VERSION ""

NS_ :

BS_:

BU_:

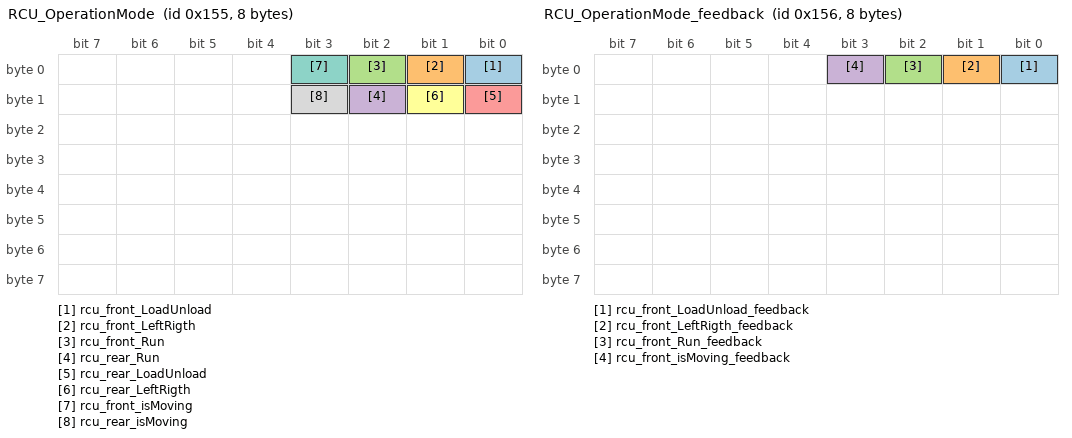
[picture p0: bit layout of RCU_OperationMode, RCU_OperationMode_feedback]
BO_ 341 RCU_OperationMode: 8 Vector__XXX
 SG_ rcu_front_LoadUnload : 0|1@1+ (1,0) [0|0] "" Vector__XXX
 SG_ rcu_front_LeftRigth : 1|1@1+ (1,0) [0|0] "" Vector__XXX
 SG_ rcu_front_Run : 2|1@1+ (1,0) [0|0] "" Vector__XXX
 SG_ rcu_rear_Run : 10|1@1+ (1,0) [0|0] "" Vector__XXX
 SG_ rcu_rear_LoadUnload : 8|1@1+ (1,0) [0|0] "" Vector__XXX
 SG_ rcu_rear_LeftRigth : 9|1@1+ (1,0) [0|0] "" Vector__XXX
 SG_ rcu_front_isMoving : 3|1@1+ (1,0) [0|0] "" Vector__XXX
 SG_ rcu_rear_isMoving : 11|1@1+ (1,0) [0|0] "" Vector__XXX

BO_ 342 RCU_OperationMode_feedback: 8 Vector__XXX
 SG_ rcu_front_LoadUnload_feedback : 0|1@1+ (1,0) [0|0] "" Vector__XXX
 SG_ rcu_front_LeftRigth_feedback : 1|1@1+ (1,0) [0|0] "" Vector__XXX
 SG_ rcu_front_Run_feedback : 2|1@1+ (1,0) [0|0] "" Vector__XXX
 SG_ rcu_front_isMoving_feedback : 3|1@1+ (1,0) [0|0] "" Vector__XXX

VAL_ 341 rcu_front_LoadUnload 1 "unload" 0 "laod" ;
VAL_ 341 rcu_front_LeftRigth 1 "left" 0 "rigth" ;
VAL_ 341 rcu_front_Run 1 "ON" 0 "OFF" ;
